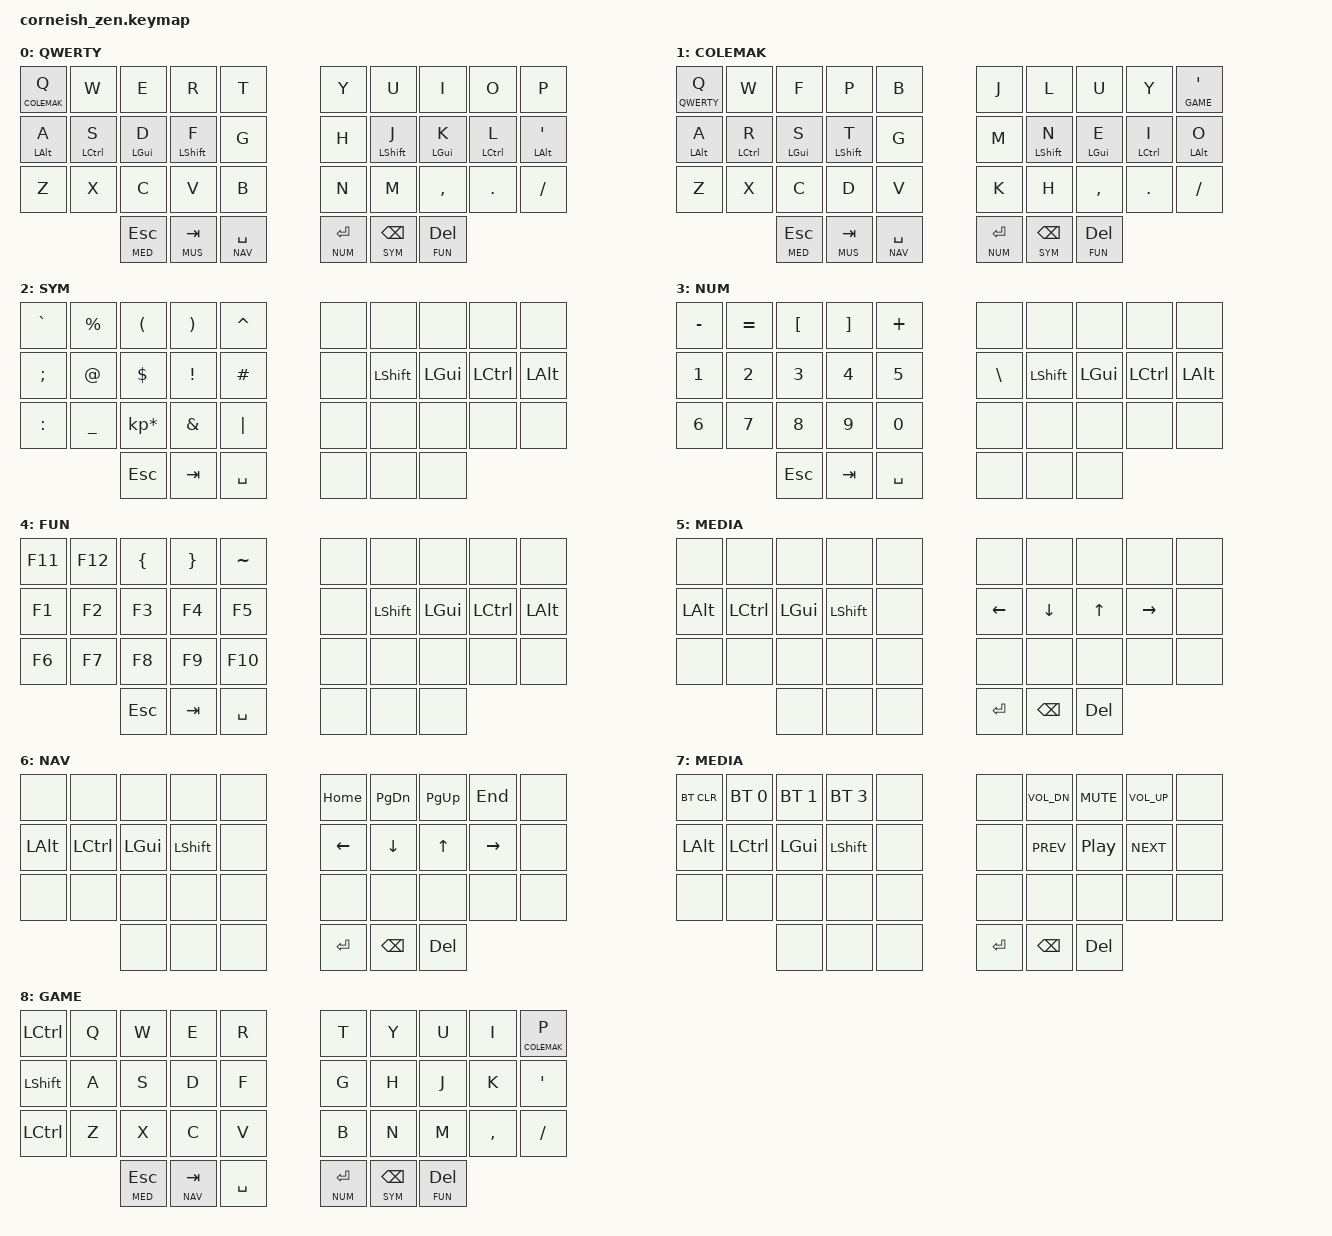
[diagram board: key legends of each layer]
#include <behaviors.dtsi>
#include <dt-bindings/zmk/keys.h>
#include <dt-bindings/zmk/bt.h>

#define QWERTY  0
#define COLEMAK 1
#define SYM     2
#define NUM     3
#define FUN     4
#define MUS     5
#define NAV     6
#define MED     7
#define GAME    8

/ {
  chosen {
    //zmk,matrix_transform = &default_transform;
    zmk,matrix_transform = &five_column_transform;
  };
};

/ {
        behaviors {
                hto: hold_to {
                        compatible = "zmk,behavior-hold-tap";
                        label = "HOLD_TO";
                        #binding-cells = <2>;
                        tapping_term_ms = <350>;
                        flavor = "tap-preferred";
                        bindings = <&to>, <&kp>;
                };
                mt_: custom_mod_tap {
                        compatible = "zmk,behavior-hold-tap";
                        label = "MOD_TAP";
                        #binding-cells = <2>;
                        flavor = "balanced";
                        tapping-term-ms = <200>;
                        quick_tap_ms = <500>;
                        bindings = <&kp>, <&kp>;
               };
        };
        keymap {
                compatible = "zmk,keymap";
                QWERTY {
                       label = "QWERTY";
// -----------------------------------------------------------------------------------------
// |  Q  |  W  |  E  |  R  |  T  |   |  Y  |  U   |  I  |  O  |  P  |
// |  A  |  S  |  D  |  F  |  G  |   |  H  |  J   |  K  |  L  |  '  |
// |  Z  |  X  |  C  |  V  |  B  |   |  N  |  M   |  ,  |  .  |  /  |
//             | ESC | SPC | TAB |   | BCK | RET  | DEL |
                        bindings = <
&hto COLEMAK Q &kp W       &kp E       &kp R         &kp T         &kp Y        &kp U       &kp I          &kp O         &kp P         
&mt_ LALT A     &mt_ LCTRL S &mt_ LGUI D  &mt_ LSHFT F   &kp G         &kp H        &mt_ LSHFT J &mt_ LGUI K     &mt_ LCTRL L   &mt_ LALT SQT  
&kp Z          &kp X       &kp C       &kp V         &kp B         &kp N        &kp M       &kp COMMA      &kp DOT       &kp FSLH      
                                        &lt MED ESC &lt MUS TAB&lt NAV SPACE    &lt NUM RET &lt SYM BKSP &lt FUN DEL
                        >;
                };
                COLEMAK {
                        label = "COLEMAK";
// -----------------------------------------------------------------------------------------
// |  Q  |  W  |  F  |  P  |  B  |   |  J  |  L   |  U  |  Y  |  ' 
// |  A  |  R  |  S  |  T  |  G  |   |  M  |  N   |  E  |  I  |  O 
// |  Z  |  X  |  C  |  D  |  V  |   |  K  |  H   |  ,  |  .  |  / 
//             | ESC | SPC | TAB |   | BCK | RET  | DEL |
                        bindings = <
   &hto QWERTY Q  &kp W             &kp       F   &kp P            &kp B             &kp J           &kp        L    &kp       U       &kp        Y      &hto GAME SQT
   &mt_ LALT   A  &mt_ LCTRL R      &mt_ LGUI S   &mt_ LSHFT T     &kp G             &kp M           &mt_ LSHFT N    &mt_ LGUI E       &mt_ LCTRL I      &mt_ LALT O    
   &kp         Z  &kp X             &kp       C   &kp D            &kp V             &kp K           &kp        H    &kp       COMMA   &kp        DOT    &kp       FSLH
                                    &lt MED   ESC &lt MUS TAB      &lt NAV    SPACE  &lt NUM    RET  &lt SYM BKSP &lt FUN DEL
                        >;
                };
                SYM {
                    label = "SYM";
// -----------------------------------------------------------------------------------------
// |     |  `  |  %  |  (  |  )  |  ^  | |     | |      |      |      |     |      |      |
// |     |  ;  |  @  |  $  |  !  |  #  | |     | |      | SHFT | META | CTR | ALT  |      |
// |     |  :  |  _  |  *  |  &  |  |  | |     | |      |      |      |     |      |      |
//                   | ESC | SPC | TAB | |     | |      |      |      |
                        bindings = <
   &kp GRAVE  &kp PRCNT    &kp LPAR        &kp RPAR       &kp CARET       &none &none     &none    &none     &none   
   &kp SEMI   &kp AT       &kp DLLR        &kp EXCL       &kp HASH        &none &kp LSHFT &kp LGUI &kp LCTRL &kp LALT
   &kp COLON  &kp UNDER    &kp KP_MULTIPLY &kp AMPS       &kp PIPE        &none &none     &none    &none     &none   
                           &kp ESC         &kp TAB        &kp SPACE       &none &none     &none
                        >;
                };
                NUM {
                    label = "NUM";
// -----------------------------------------------------------------------------------------
// |     |  -  |  =  |  [  |  ]  |  +  | |     | |      |      |      |     |      |      |
// |     |  1  |  2  |  3  |  4  |  5  | |     | |  \   | SHFT | META | CTR | ALT  |      |
// |     |  6  |  7  |  8  |  9  |  0  | |     | |      |      |      |     |      |      |
//                   | ESC | SPC | TAB | |     | |      |      |      |
                        bindings = <
   &kp MINUS &kp EQUAL    &kp LBKT        &kp RBKT       &kp PLUS      &none    &none     &none    &none     &none   
   &kp N1    &kp N2       &kp N3          &kp N4         &kp N5        &kp BSLH &kp LSHFT &kp LGUI &kp LCTRL &kp LALT
   &kp N6    &kp N7       &kp N8          &kp N9         &kp N0        &none    &none     &none    &none     &none   
                          &kp ESC         &kp TAB        &kp SPACE     &none    &none     &none
                        >;
                };
                FUN {
                    label = "FUN";
// -----------------------------------------------------------------------------------------
// |     | F11 | F12 |  {  |  }  |  ~  | |     | |      |      |      |     |      |      |
// |     | F1  | F2  | F3  | F4  | F5  | |     | |      | SHFT | META | CTR | ALT  |      |
// |     | F6  | F7  | F8  | F9  | F10 | |     | |      |      |      |     |      |      |
//                   | ESC | SPC | TAB | |     | |      |      |      |
                        bindings = <
   &kp F11   &kp F12      &kp LBRC        &kp RBRC       &kp TILDE     &none &none     &none    &none     &none   
   &kp F1    &kp F2       &kp F3          &kp F4         &kp F5        &none &kp LSHFT &kp LGUI &kp LCTRL &kp LALT
   &kp F6    &kp F7       &kp F8          &kp F9         &kp F10       &none &none     &none    &none     &none   
                          &kp ESC         &kp TAB        &kp SPACE     &none &none     &none
                        >;
                };
                MUS {
                    label = "MEDIA";
// -----------------------------------------------------------------------------------------
// |     |     |     |      |      |     | |     | |      |      |      |     |      |      |
// |     | ALT | CTR | META | SHFT |     | |     | | ML   | MD   | MU   | MR  |      |      |
// |     |     |     |      |      |     | |     | | DL   | DD   | DU   | DR  |      |      |
//                   |      |      |     | |     | | BKSP | RET  | DEL  |
                        bindings = <
   &none     &none     &none    &none     &none         &none           &none        &none       &none       &none
   &kp LALT &kp LCTRL  &kp LGUI &kp LSHFT &none         &kp LEFT        &kp DOWN     &kp UP      &kp RIGHT   &none
   &none    &none      &none    &none     &none         &none           &none        &none       &none       &none
                       &none    &none     &none         &kp RET         &kp BKSP     &kp DEL
                        >;
                };
                NAV {
                    label = "NAV";
// -----------------------------------------------------------------------------------------
// |     |     |     |      |      |     | |     | | HOME | PGDN | PGUP | END |      |      |
// |     | ALT | CTR | META | SHFT |     | |     | | LEFT | DOWN | UP   | RHT |      |      |
// |     |     |     |      |      |     | |     | |      |      |      |     |      |      |
//                   |      |      |     | |     | | BKSP | RET  | DEL  |
                              bindings = <
   &none    &none     &none    &none     &none         &kp HOME        &kp PG_DN    &kp PG_UP   &kp END     &none
   &kp LALT &kp LCTRL &kp LGUI &kp LSHFT &none         &kp LEFT        &kp DOWN     &kp UP      &kp RIGHT   &none
   &none    &none     &none    &none     &none         &none           &none        &none       &none       &none
                      &none    &none     &none         &kp RET         &kp BKSP     &kp DEL
                        >;
                };
                MED {
                    label = "MEDIA";
// -----------------------------------------------------------------------------------------
// |     | CLR | BT1 | BT2  | BT3  |     | |     | |      | VOLD | MUTE | VOLU |      |      |
// |     | ALT | CTR | META | SHFT |     | |     | |      | PREV | PP   | NEXT |      |      |
// |     |     |     |      |      |     | |     | |      |      |      |      |      |      |
//                   |      |      |     | |     | | BKSP | RET  | DEL  |
                        bindings = <
   &bt BT_CLR   &bt BT_SEL 0 &bt BT_SEL 1 &bt BT_SEL 3 &none         &none           &kp C_VOL_DN &kp C_MUTE  &kp C_VOL_UP &none
   &kp LALT     &kp LCTRL    &kp LGUI     &kp LSHFT    &none         &none           &kp C_PREV   &kp C_PP    &kp C_NEXT   &none
   &none        &none        &none        &none        &none         &none           &none        &none       &none        &none
                             &none        &none        &none         &kp RET         &kp BKSP     &kp DEL
                        >;
                };
                GAME {
                     label = "GAME";
// -----------------------------------------------------------------------------------------
// |      |  Q  |  W  |  E  |  R  |  T  |   |  Y  |  U   |  I  |  O  |  P  |      |
// |      |  A  |  S  |  D  |  F  |  G  |   |  H  |  J   |  K  |  L  |  '  |      |
// |      |  Z  |  X  |  C  |  V  |  B  |   |  N  |  M   |  ,  |  .  |  /  |      |
//                    | ESC | SPC | TAB |   | BCK | RET  | DEL |
                        bindings = <
   &kp LCTRL &kp Q          &kp W       &kp E       &kp R         &kp T         &kp Y        &kp U       &kp I         &hto COLEMAK P
   &kp LSHFT &kp A          &kp S       &kp D       &kp F         &kp G         &kp H        &kp J       &kp K         &kp SQT       
   &kp LCTRL &kp Z          &kp X       &kp C       &kp V         &kp B         &kp N        &kp M       &kp COMMA     &kp FSLH      
                                        &lt MED ESC &lt NAV TAB   &kp SPACE     &lt NUM RET &lt SYM BKSP &lt FUN DEL
                        >;
                };
        };
};
